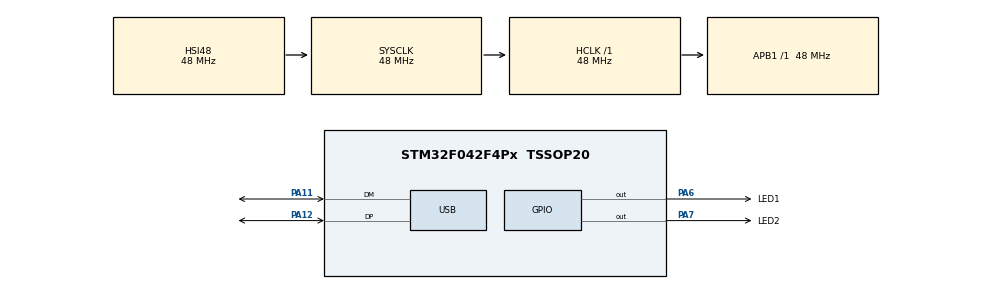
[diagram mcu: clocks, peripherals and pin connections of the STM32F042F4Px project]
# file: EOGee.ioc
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Mcu.Family=STM32F0
Mcu.Name=STM32F042F4Px
Mcu.Package=TSSOP20
NVIC.USB_IRQn=true\:0\:0\:false\:false\:true\:false\:true
PA11.Mode=Device
PA11.Signal=USB_DM
PA12.Mode=Device
PA12.Signal=USB_DP
PA6.GPIO_Label=LED1
PA6.Signal=GPIO_Output
PA7.GPIO_Label=LED2
PA7.Signal=GPIO_Output
ProjectManager.HeapSize=0x150
ProjectManager.StackSize=0x350
ProjectManager.TargetToolchain=SW4STM32
RCC.AHBFreq_Value=48000000
RCC.APB1Freq_Value=48000000
RCC.APB1TimFreq_Value=48000000
RCC.HCLKFreq_Value=48000000
RCC.SYSCLKFreq_VALUE=48000000
RCC.SYSCLKSource=RCC_SYSCLKSOURCE_HSI48
USB_DEVICE.CLASS_NAME_FS=CDC
USB_DEVICE.VirtualMode=Cdc
USB_DEVICE.VirtualModeFS=Cdc_FS
VP_SYS_VS_PINREMAP.Mode=PINREMAP
VP_USB_DEVICE_VS_USB_DEVICE_CDC_FS.Mode=CDC_FS
board=custom

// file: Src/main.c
/* USER CODE BEGIN Header */
/**
  ******************************************************************************
  * @file           : main.c
  * @brief          : Main program body
  ******************************************************************************
  * @attention
  *
  * <h2><center>&copy; Copyright (c) 2020 STMicroelectronics.
  * All rights reserved.</center></h2>
  *
  * This software component is licensed by ST under Ultimate Liberty license
  * SLA0044, the "License"; You may not use this file except in compliance with
  * the License. You may obtain a copy of the License at:
  *                             www.st.com/SLA0044
  *
  ******************************************************************************
  */
/* USER CODE END Header */

#include "main.h"
#include "usb_device.h"
#include "usbd_cdc_if.h"

void SystemClock_Config(void);
static void MX_GPIO_Init(void);

int main(void)
{

  /* MCU Configuration--------------------------------------------------------*/

  /* Reset of all peripherals, Initializes the Flash interface and the Systick. */
  HAL_Init();

  /* Configure the system clock */
  SystemClock_Config();

  /* Initialize all configured peripherals */
  MX_GPIO_Init();
  MX_USB_DEVICE_Init();
  /* USER CODE BEGIN 2 */
  HAL_Delay(3000);
  CDC_Transmit_FS((uint8_t*)"Hello\n\r", 7);

  HAL_GPIO_WritePin(GPIOA, LED1_Pin, GPIO_PIN_SET);
  HAL_GPIO_WritePin(GPIOA, LED2_Pin, GPIO_PIN_RESET);
  /* USER CODE END 2 */

  /* Infinite loop */
  /* USER CODE BEGIN WHILE */
  uint8_t i = 0;
  while (1)
  {
    /* USER CODE END WHILE */

    /* USER CODE BEGIN 3 */
	  i += 1;
	  CDC_Transmit_FS(&i, 1);
	  if(i == 0)
	  {
		  HAL_GPIO_TogglePin(GPIOA, LED1_Pin);
		  HAL_GPIO_TogglePin(GPIOA, LED2_Pin);
	  }
	  HAL_Delay(1);
  }
  /* USER CODE END 3 */
}

void SystemClock_Config(void)
{
  RCC_OscInitTypeDef RCC_OscInitStruct = {0};
  RCC_ClkInitTypeDef RCC_ClkInitStruct = {0};
  RCC_PeriphCLKInitTypeDef PeriphClkInit = {0};

  /** Initializes the CPU, AHB and APB busses clocks
  */
  RCC_OscInitStruct.OscillatorType = RCC_OSCILLATORTYPE_HSI48;
  RCC_OscInitStruct.HSI48State = RCC_HSI48_ON;
  RCC_OscInitStruct.PLL.PLLState = RCC_PLL_NONE;
  if (HAL_RCC_OscConfig(&RCC_OscInitStruct) != HAL_OK)
  {
    Error_Handler();
  }
  /** Initializes the CPU, AHB and APB busses clocks
  */
  RCC_ClkInitStruct.ClockType = RCC_CLOCKTYPE_HCLK|RCC_CLOCKTYPE_SYSCLK
                              |RCC_CLOCKTYPE_PCLK1;
  RCC_ClkInitStruct.SYSCLKSource = RCC_SYSCLKSOURCE_HSI48;
  RCC_ClkInitStruct.AHBCLKDivider = RCC_SYSCLK_DIV1;
  RCC_ClkInitStruct.APB1CLKDivider = RCC_HCLK_DIV1;

  if (HAL_RCC_ClockConfig(&RCC_ClkInitStruct, FLASH_LATENCY_1) != HAL_OK)
  {
    Error_Handler();
  }
  PeriphClkInit.PeriphClockSelection = RCC_PERIPHCLK_USB;
  PeriphClkInit.UsbClockSelection = RCC_USBCLKSOURCE_HSI48;

  if (HAL_RCCEx_PeriphCLKConfig(&PeriphClkInit) != HAL_OK)
  {
    Error_Handler();
  }
}

static void MX_GPIO_Init(void)
{
  GPIO_InitTypeDef GPIO_InitStruct = {0};

  /* GPIO Ports Clock Enable */
  __HAL_RCC_GPIOA_CLK_ENABLE();

  /*Configure GPIO pin Output Level */
  HAL_GPIO_WritePin(GPIOA, LED1_Pin|LED2_Pin, GPIO_PIN_RESET);

  /*Configure GPIO pins : LED1_Pin LED2_Pin */
  GPIO_InitStruct.Pin = LED1_Pin|LED2_Pin;
  GPIO_InitStruct.Mode = GPIO_MODE_OUTPUT_PP;
  GPIO_InitStruct.Pull = GPIO_NOPULL;
  GPIO_InitStruct.Speed = GPIO_SPEED_FREQ_LOW;
  HAL_GPIO_Init(GPIOA, &GPIO_InitStruct);

}

void Error_Handler(void)
{
}

/************************ (C) COPYRIGHT STMicroelectronics *****END OF FILE****/
